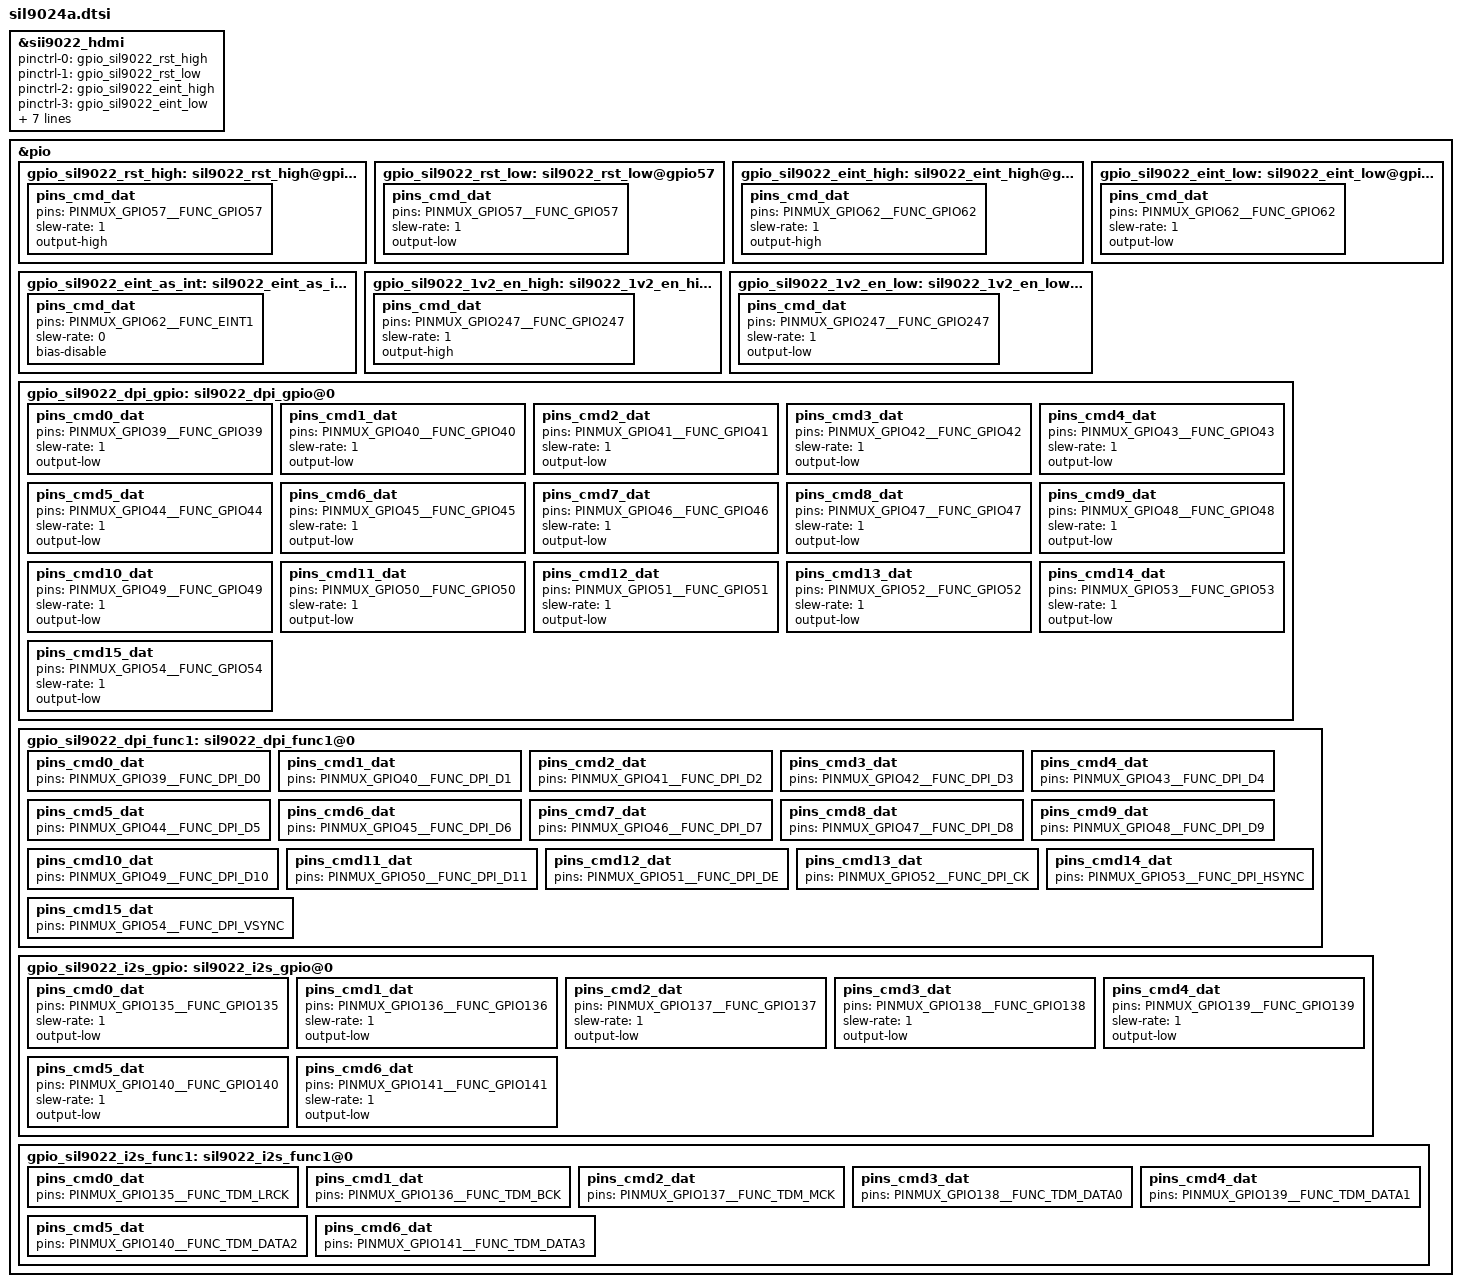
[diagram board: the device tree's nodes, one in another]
&sii9022_hdmi {
	pinctrl-names = "sil9022_rst_high","sil9022_rst_low","sil9022_eint_high","sil9022_eint_low","sil9022_eint_as_int",
			"sil9022_1v2_en_high","sil9022_1v2_en_low","sil9022_dpi_gpio","sil9022_dpi_func1","sil9022_i2s_gpio","sil9022_i2s_func1";		
	pinctrl-0 = <&gpio_sil9022_rst_high>;
	pinctrl-1 = <&gpio_sil9022_rst_low>;
	pinctrl-2 = <&gpio_sil9022_eint_high>;
	pinctrl-3 = <&gpio_sil9022_eint_low>;
	pinctrl-4 = <&gpio_sil9022_eint_as_int>;
	pinctrl-5 = <&gpio_sil9022_1v2_en_high>;
	pinctrl-6 = <&gpio_sil9022_1v2_en_low>;
	pinctrl-7 = <&gpio_sil9022_dpi_gpio>;
	pinctrl-8 = <&gpio_sil9022_dpi_func1>;
	pinctrl-9 = <&gpio_sil9022_i2s_gpio>;
	pinctrl-10 = <&gpio_sil9022_i2s_func1>;	
	status = "okay";
};

&pio {

	gpio_sil9022_rst_high:sil9022_rst_high@gpio57 {
		pins_cmd_dat {
			pins = <PINMUX_GPIO57__FUNC_GPIO57>;
			slew-rate = <1>;
			output-high;
		};
	};

	gpio_sil9022_rst_low:sil9022_rst_low@gpio57 {
		pins_cmd_dat {
			pins = <PINMUX_GPIO57__FUNC_GPIO57>;
			slew-rate = <1>;
			output-low;
		};
	};
	
	gpio_sil9022_eint_high:sil9022_eint_high@gpio62 {
		pins_cmd_dat {
			pins = <PINMUX_GPIO62__FUNC_GPIO62>;
			slew-rate = <1>;
			output-high;
		};
	};

	gpio_sil9022_eint_low:sil9022_eint_low@gpio62 {
		pins_cmd_dat {
			pins = <PINMUX_GPIO62__FUNC_GPIO62>;
			slew-rate = <1>;
			output-low;
		};
	};
	
	gpio_sil9022_eint_as_int:sil9022_eint_as_int@0 {
		pins_cmd_dat {
			pins = <PINMUX_GPIO62__FUNC_EINT1>;
			slew-rate = <0>;
			bias-disable;
		};
	};	

	gpio_sil9022_1v2_en_high:sil9022_1v2_en_high@gpio247 {
		pins_cmd_dat {
			pins = <PINMUX_GPIO247__FUNC_GPIO247>;
			slew-rate = <1>;
			output-high;
		};
	};
	
	gpio_sil9022_1v2_en_low:sil9022_1v2_en_low@gpio247 {
		pins_cmd_dat {
			pins = <PINMUX_GPIO247__FUNC_GPIO247>;
			slew-rate = <1>;
			output-low;
		};
	};	

	gpio_sil9022_dpi_gpio: sil9022_dpi_gpio@0 {
		pins_cmd0_dat {
			pins = <PINMUX_GPIO39__FUNC_GPIO39>;
			slew-rate = <1>;
			output-low;
		};
		pins_cmd1_dat {
			pins = <PINMUX_GPIO40__FUNC_GPIO40>;
			slew-rate = <1>;
			output-low;
		};
		pins_cmd2_dat {
			pins = <PINMUX_GPIO41__FUNC_GPIO41>;
			slew-rate = <1>;
			output-low;
		};
		pins_cmd3_dat {
			pins = <PINMUX_GPIO42__FUNC_GPIO42>;
			slew-rate = <1>;
			output-low;
		};
		pins_cmd4_dat {
			pins = <PINMUX_GPIO43__FUNC_GPIO43>;
			slew-rate = <1>;
			output-low;
		};
		pins_cmd5_dat {
			pins = <PINMUX_GPIO44__FUNC_GPIO44>;
			slew-rate = <1>;
			output-low;
		};
		pins_cmd6_dat {
			pins = <PINMUX_GPIO45__FUNC_GPIO45>;
			slew-rate = <1>;
			output-low;
		};
		pins_cmd7_dat {
			pins = <PINMUX_GPIO46__FUNC_GPIO46>;
			slew-rate = <1>;
			output-low;
		};
		pins_cmd8_dat {
			pins = <PINMUX_GPIO47__FUNC_GPIO47>;
			slew-rate = <1>;
			output-low;
		};
		pins_cmd9_dat {
			pins = <PINMUX_GPIO48__FUNC_GPIO48>;
			slew-rate = <1>;
			output-low;
		};
		pins_cmd10_dat {
			pins = <PINMUX_GPIO49__FUNC_GPIO49>;
			slew-rate = <1>;
			output-low;
		};
		pins_cmd11_dat {
			pins = <PINMUX_GPIO50__FUNC_GPIO50>;
			slew-rate = <1>;
			output-low;
		};
		pins_cmd12_dat {
			pins = <PINMUX_GPIO51__FUNC_GPIO51>;
			slew-rate = <1>;
			output-low;
		};
		pins_cmd13_dat {
			pins = <PINMUX_GPIO52__FUNC_GPIO52>;
			slew-rate = <1>;
			output-low;
		};
		pins_cmd14_dat {
			pins = <PINMUX_GPIO53__FUNC_GPIO53>;
			slew-rate = <1>;
			output-low;
		};
		pins_cmd15_dat {
			pins = <PINMUX_GPIO54__FUNC_GPIO54>;
			slew-rate = <1>;
			output-low;
		};
	};
	
	gpio_sil9022_dpi_func1: sil9022_dpi_func1@0 {
		pins_cmd0_dat {
			pins = <PINMUX_GPIO39__FUNC_DPI_D0>;
		};
		pins_cmd1_dat {
			pins = <PINMUX_GPIO40__FUNC_DPI_D1>;
		};
		pins_cmd2_dat {
			pins = <PINMUX_GPIO41__FUNC_DPI_D2>;
		};
		pins_cmd3_dat {
			pins = <PINMUX_GPIO42__FUNC_DPI_D3>;
		};
		pins_cmd4_dat {
			pins = <PINMUX_GPIO43__FUNC_DPI_D4>;
		};
		pins_cmd5_dat {
			pins = <PINMUX_GPIO44__FUNC_DPI_D5>;
		};
		pins_cmd6_dat {
			pins = <PINMUX_GPIO45__FUNC_DPI_D6>;
		};
		pins_cmd7_dat {
			pins = <PINMUX_GPIO46__FUNC_DPI_D7>;
		};
		pins_cmd8_dat {
			pins = <PINMUX_GPIO47__FUNC_DPI_D8>;
		};
		pins_cmd9_dat {
			pins = <PINMUX_GPIO48__FUNC_DPI_D9>;
		};
		pins_cmd10_dat {
			pins = <PINMUX_GPIO49__FUNC_DPI_D10>;
		};
		pins_cmd11_dat {
			pins = <PINMUX_GPIO50__FUNC_DPI_D11>;
		};
		pins_cmd12_dat {
			pins = <PINMUX_GPIO51__FUNC_DPI_DE>;
		};
		pins_cmd13_dat {
			pins = <PINMUX_GPIO52__FUNC_DPI_CK>;
		};
		pins_cmd14_dat {
			pins = <PINMUX_GPIO53__FUNC_DPI_HSYNC>;
		};
		pins_cmd15_dat {
			pins = <PINMUX_GPIO54__FUNC_DPI_VSYNC>;
		};
	};

	gpio_sil9022_i2s_gpio: sil9022_i2s_gpio@0 {
		pins_cmd0_dat {
			pins = <PINMUX_GPIO135__FUNC_GPIO135>;
			slew-rate = <1>;
			output-low;
		};
		pins_cmd1_dat {
			pins = <PINMUX_GPIO136__FUNC_GPIO136>;
			slew-rate = <1>;
			output-low;
		};
		pins_cmd2_dat {
			pins = <PINMUX_GPIO137__FUNC_GPIO137>;
			slew-rate = <1>;
			output-low;
		};
		pins_cmd3_dat {
			pins = <PINMUX_GPIO138__FUNC_GPIO138>;
			slew-rate = <1>;
			output-low;
		};
		pins_cmd4_dat {
			pins = <PINMUX_GPIO139__FUNC_GPIO139>;
			slew-rate = <1>;
			output-low;
		};
		pins_cmd5_dat {
			pins = <PINMUX_GPIO140__FUNC_GPIO140>;
			slew-rate = <1>;
			output-low;
		};
		pins_cmd6_dat {
			pins = <PINMUX_GPIO141__FUNC_GPIO141>;
			slew-rate = <1>;
			output-low;
		};
	};
	
	gpio_sil9022_i2s_func1: sil9022_i2s_func1@0 {
		pins_cmd0_dat {
			pins = <PINMUX_GPIO135__FUNC_TDM_LRCK>;
		};
		pins_cmd1_dat {
			pins = <PINMUX_GPIO136__FUNC_TDM_BCK>;
		};
		pins_cmd2_dat {
			pins = <PINMUX_GPIO137__FUNC_TDM_MCK>;
		};
		pins_cmd3_dat {
			pins = <PINMUX_GPIO138__FUNC_TDM_DATA0>;
		};
		pins_cmd4_dat {
			pins = <PINMUX_GPIO139__FUNC_TDM_DATA1>;
		};
		pins_cmd5_dat {
			pins = <PINMUX_GPIO140__FUNC_TDM_DATA2>;
		};
		pins_cmd6_dat {
			pins = <PINMUX_GPIO141__FUNC_TDM_DATA3>;
		};
	};
	
};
